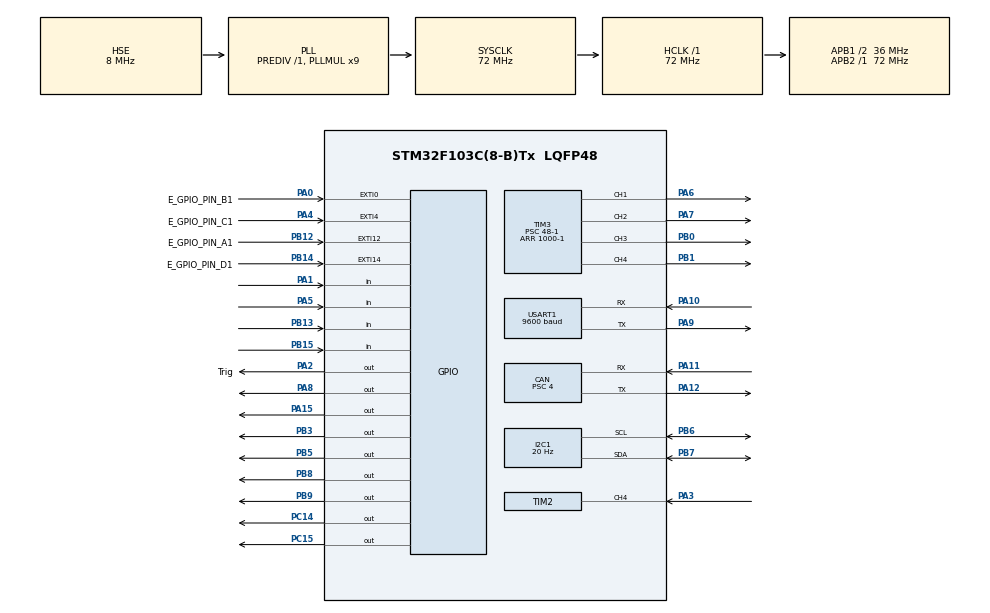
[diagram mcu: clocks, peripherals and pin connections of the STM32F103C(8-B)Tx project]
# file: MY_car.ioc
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CAN.BS1=CAN_BS1_3TQ
CAN.BS2=CAN_BS2_5TQ
CAN.CalculateBaudRate=1000000
CAN.CalculateTimeBit=1000
CAN.CalculateTimeQuantum=111.11111111111111
CAN.Prescaler=4
FREERTOS.Tasks01=defaultTask,24,128,StartDefaultTask,Default,NULL,Dynamic,NULL,NULL
FREERTOS.configTOTAL_HEAP_SIZE=8000
I2C1.ClockSpeed=20
Mcu.Family=STM32F1
Mcu.Name=STM32F103C(8-B)Tx
Mcu.Package=LQFP48
NVIC.EXTI0_IRQn=true\:5\:0\:false\:false\:true\:true\:true\:true\:true
NVIC.EXTI15_10_IRQn=true\:5\:0\:false\:false\:true\:true\:true\:true\:true
NVIC.EXTI4_IRQn=true\:5\:0\:false\:false\:true\:true\:true\:true\:true
NVIC.PriorityGroup=NVIC_PRIORITYGROUP_4
NVIC.TIM1_UP_IRQn=true\:5\:0\:false\:false\:true\:true\:true\:true\:true
NVIC.TIM2_IRQn=true\:5\:0\:false\:false\:true\:true\:true\:true\:true
NVIC.TIM4_IRQn=true\:15\:0\:false\:false\:true\:false\:false\:true\:true
NVIC.TimeBase=TIM4_IRQn
NVIC.TimeBaseIP=TIM4
NVIC.USART1_IRQn=true\:5\:0\:false\:false\:true\:true\:true\:true\:true
NVIC.USB_LP_CAN1_RX0_IRQn=true\:5\:0\:false\:false\:true\:true\:true\:true\:true
PA0-WKUP.GPIO_Label=E_GPIO_PIN_B1
PA0-WKUP.GPIO_ModeDefaultEXTI=GPIO_MODE_IT_RISING_FALLING
PA0-WKUP.GPIO_PuPd=GPIO_PULLUP
PA0-WKUP.Signal=GPXTI0
PA1.GPIO_PuPd=GPIO_PULLUP
PA1.Signal=GPIO_Input
PA10.Mode=Asynchronous
PA10.Signal=USART1_RX
PA11.Mode=CAN_Activate
PA11.Signal=CAN_RX
PA12.Mode=CAN_Activate
PA12.Signal=CAN_TX
PA13.Mode=Serial_Wire
PA13.Signal=SYS_JTMS-SWDIO
PA14.Mode=Serial_Wire
PA14.Signal=SYS_JTCK-SWCLK
PA15.Signal=GPIO_Output
PA2.GPIO_Label=Trig
PA2.GPIO_Speed=GPIO_SPEED_FREQ_HIGH
PA2.PinState=GPIO_PIN_RESET
PA2.Signal=GPIO_Output
PA3.Signal=S_TIM2_CH4
PA4.GPIO_Label=E_GPIO_PIN_C1
PA4.GPIO_ModeDefaultEXTI=GPIO_MODE_IT_RISING_FALLING
PA4.GPIO_PuPd=GPIO_PULLUP
PA4.Signal=GPXTI4
PA5.GPIO_PuPd=GPIO_PULLUP
PA5.Signal=GPIO_Input
PA6.Signal=S_TIM3_CH1
PA7.Signal=S_TIM3_CH2
PA8.Signal=GPIO_Output
PA9.Mode=Asynchronous
PA9.Signal=USART1_TX
PB0.Signal=S_TIM3_CH3
PB1.Signal=S_TIM3_CH4
PB12.GPIO_Label=E_GPIO_PIN_A1
PB12.GPIO_ModeDefaultEXTI=GPIO_MODE_IT_RISING_FALLING
PB12.GPIO_PuPd=GPIO_PULLUP
PB12.Signal=GPXTI12
PB13.GPIO_PuPd=GPIO_PULLUP
PB13.Signal=GPIO_Input
PB14.GPIO_Label=E_GPIO_PIN_D1
PB14.GPIO_ModeDefaultEXTI=GPIO_MODE_IT_RISING_FALLING
PB14.GPIO_PuPd=GPIO_PULLUP
PB14.Signal=GPXTI14
PB15.GPIO_PuPd=GPIO_PULLUP
PB15.Signal=GPIO_Input
PB3.Signal=GPIO_Output
PB5.Signal=GPIO_Output
PB6.Mode=I2C
PB6.Signal=I2C1_SCL
PB7.Mode=I2C
PB7.Signal=I2C1_SDA
PB8.Signal=GPIO_Output
PB9.Signal=GPIO_Output
PC14-OSC32_IN.Signal=GPIO_Output
PC15-OSC32_OUT.Signal=GPIO_Output
PD0-OSC_IN.Mode=HSE-External-Oscillator
PD0-OSC_IN.Signal=RCC_OSC_IN
PD1-OSC_OUT.Mode=HSE-External-Oscillator
PD1-OSC_OUT.Signal=RCC_OSC_OUT
ProjectManager.HeapSize=0x200
ProjectManager.StackSize=0x400
ProjectManager.TargetToolchain=MDK-ARM V5.32
RCC.AHBFreq_Value=72000000
RCC.APB1CLKDivider=RCC_HCLK_DIV2
RCC.APB1Freq_Value=36000000
RCC.APB1TimFreq_Value=72000000
RCC.APB2Freq_Value=72000000
RCC.APB2TimFreq_Value=72000000
RCC.HCLKFreq_Value=72000000
RCC.PLLMUL=RCC_PLL_MUL9
RCC.PLLSourceVirtual=RCC_PLLSOURCE_HSE
RCC.SYSCLKFreq_VALUE=72000000
RCC.SYSCLKSource=RCC_SYSCLKSOURCE_PLLCLK
RCC.USBFreq_Value=72000000
SH.S_TIM2_CH4.0=TIM2_CH4,Input_Capture4_from_TI4
SH.S_TIM3_CH1.0=TIM3_CH1,PWM Generation1 CH1
SH.S_TIM3_CH2.0=TIM3_CH2,PWM Generation2 CH2
SH.S_TIM3_CH3.0=TIM3_CH3,PWM Generation3 CH3
SH.S_TIM3_CH4.0=TIM3_CH4,PWM Generation4 CH4
TIM1.AutoReloadPreload=TIM_AUTORELOAD_PRELOAD_ENABLE
TIM1.Period=10000-1
TIM1.Prescaler=72-1
TIM2.AutoReloadPreload=TIM_AUTORELOAD_PRELOAD_ENABLE
TIM2.Channel-Input_Capture4_from_TI4=TIM_CHANNEL_4
TIM2.Period=65535
TIM2.Prescaler=72-1
TIM2.TIM_MasterSlaveMode=TIM_MASTERSLAVEMODE_DISABLE
TIM3.Channel-PWM\ Generation1\ CH1=TIM_CHANNEL_1
TIM3.Channel-PWM\ Generation2\ CH2=TIM_CHANNEL_2
TIM3.Channel-PWM\ Generation3\ CH3=TIM_CHANNEL_3
TIM3.Channel-PWM\ Generation4\ CH4=TIM_CHANNEL_4
TIM3.Period=1000-1
TIM3.Prescaler=48-1
USART1.BaudRate=9600
USART1.VirtualMode=VM_ASYNC
VP_FREERTOS_VS_CMSIS_V2.Mode=CMSIS_V2
VP_SYS_VS_tim4.Mode=TIM4
VP_TIM1_VS_ClockSourceINT.Mode=Internal
VP_TIM2_VS_ClockSourceINT.Mode=Internal
board=custom

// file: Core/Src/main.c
/* USER CODE BEGIN Header */
/**
 ******************************************************************************
 * @file           : main.c
 * @brief          : Main program body
 ******************************************************************************
 * @attention
 *
 * Copyright (c) 2024 STMicroelectronics.
 * All rights reserved.
 *
 * This software is licensed under terms that can be found in the LICENSE file
 * in the root directory of this software component.
 * If no LICENSE file comes with this software, it is provided AS-IS.
 *
 ******************************************************************************
 */
/* USER CODE END Header */
#include "main.h"
#include "cmsis_os.h"
#include "can.h"
#include "i2c.h"
#include "tim.h"
#include "usart.h"
#include "gpio.h"

void SystemClock_Config(void);
void MX_FREERTOS_Init(void);
/* USER CODE BEGIN PFP */
extern void Motor_Timer_ISR(void);
/* USER CODE END PFP */

int main(void)
{

  /* MCU Configuration--------------------------------------------------------*/

  /* Reset of all peripherals, Initializes the Flash interface and the Systick. */
  HAL_Init();

  /* Configure the system clock */
  SystemClock_Config();

  /* Initialize all configured peripherals */
  MX_GPIO_Init();
  MX_TIM3_Init();
  MX_I2C1_Init();
  MX_USART1_UART_Init();
  MX_TIM2_Init();
  MX_TIM1_Init();
  MX_CAN_Init();
  /* USER CODE BEGIN 2 */
  /*使能定时中断*/

  /* USER CODE END 2 */

  /* Init scheduler */
  osKernelInitialize();

  /* Call init function for freertos objects (in cmsis_os2.c) */
  MX_FREERTOS_Init();

  /* Start scheduler */
  osKernelStart();

  /* We should never get here as control is now taken by the scheduler */

  /* Infinite loop */
  while (1)
  {

  }
}

void SystemClock_Config(void)
{
  RCC_OscInitTypeDef RCC_OscInitStruct = {0};
  RCC_ClkInitTypeDef RCC_ClkInitStruct = {0};

  /** Initializes the RCC Oscillators according to the specified parameters
  * in the RCC_OscInitTypeDef structure.
  */
  RCC_OscInitStruct.OscillatorType = RCC_OSCILLATORTYPE_HSE;
  RCC_OscInitStruct.HSEState = RCC_HSE_ON;
  RCC_OscInitStruct.HSEPredivValue = RCC_HSE_PREDIV_DIV1;
  RCC_OscInitStruct.HSIState = RCC_HSI_ON;
  RCC_OscInitStruct.PLL.PLLState = RCC_PLL_ON;
  RCC_OscInitStruct.PLL.PLLSource = RCC_PLLSOURCE_HSE;
  RCC_OscInitStruct.PLL.PLLMUL = RCC_PLL_MUL9;
  if (HAL_RCC_OscConfig(&RCC_OscInitStruct) != HAL_OK)
  {
    Error_Handler();
  }

  /** Initializes the CPU, AHB and APB buses clocks
  */
  RCC_ClkInitStruct.ClockType = RCC_CLOCKTYPE_HCLK|RCC_CLOCKTYPE_SYSCLK
                              |RCC_CLOCKTYPE_PCLK1|RCC_CLOCKTYPE_PCLK2;
  RCC_ClkInitStruct.SYSCLKSource = RCC_SYSCLKSOURCE_PLLCLK;
  RCC_ClkInitStruct.AHBCLKDivider = RCC_SYSCLK_DIV1;
  RCC_ClkInitStruct.APB1CLKDivider = RCC_HCLK_DIV2;
  RCC_ClkInitStruct.APB2CLKDivider = RCC_HCLK_DIV1;

  if (HAL_RCC_ClockConfig(&RCC_ClkInitStruct, FLASH_LATENCY_2) != HAL_OK)
  {
    Error_Handler();
  }
}

void HAL_TIM_PeriodElapsedCallback(TIM_HandleTypeDef *htim)
{
  if (htim->Instance == TIM4) {
    HAL_IncTick();
  }
  /* USER CODE BEGIN Callback 1 */
  if (htim->Instance == TIM1)
  {
    Motor_Timer_ISR();
  }
  if (htim->Instance == TIM2)
  {

  }
  /* USER CODE END Callback 1 */
}

void Error_Handler(void)
{
  __disable_irq();
  while (1)
  {
  }
}
